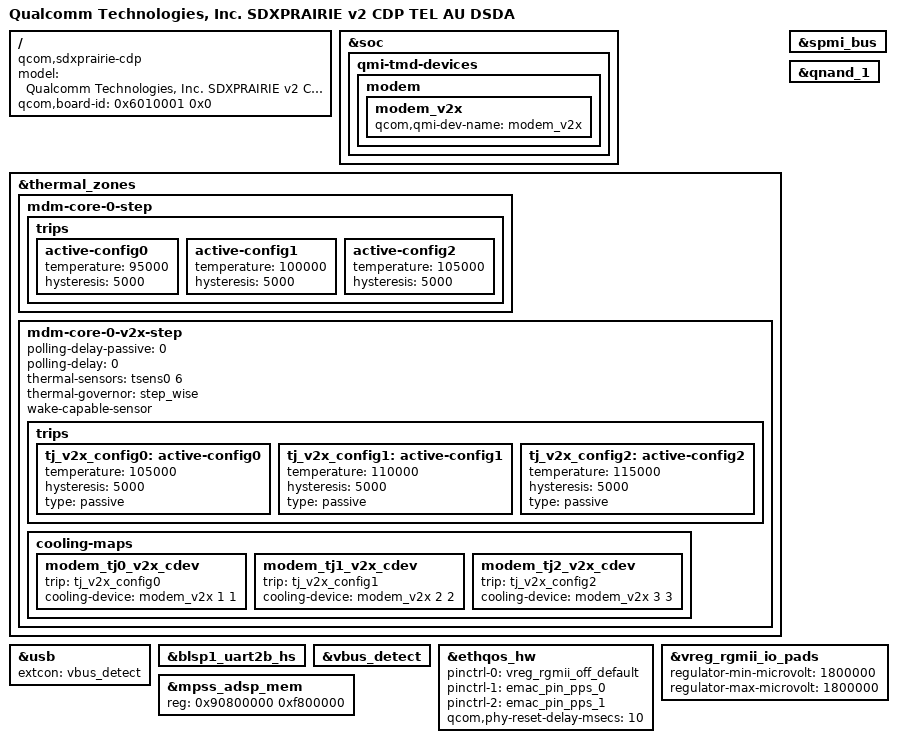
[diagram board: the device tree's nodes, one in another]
/* Copyright (c) 2020, The Linux Foundation. All rights reserved.
 *
 * This program is free software; you can redistribute it and/or modify
 * it under the terms of the GNU General Public License version 2 and
 * only version 2 as published by the Free Software Foundation.
 *
 * This program is distributed in the hope that it will be useful,
 * but WITHOUT ANY WARRANTY; without even the implied warranty of
 * MERCHANTABILITY or FITNESS FOR A PARTICULAR PURPOSE.  See the
 * GNU General Public License for more details.
 */

/dts-v1/;

#include "sdxprairie-v2.dtsi"
#include "sdxprairie-cdp.dtsi"

/ {
	model = "Qualcomm Technologies, Inc. SDXPRAIRIE v2 CDP TEL AU DSDA";
	compatible = "qcom,sdxprairie-cdp",
		"qcom,sdxprairie", "qcom,cdp";
	qcom,board-id = <0x6010001 0x0>;
};

&soc {
	qmi-tmd-devices {
		modem {
			modem_v2x: modem_v2x {
				qcom,qmi-dev-name = "modem_v2x";
				#cooling-cells = <2>;
			};
		};
	};
};

/* delete pm8150b nodes */
&thermal_zones {
	/delete-node/ pm8150b-wp-therm;
	/delete-node/ pm8150b_tz;
	/delete-node/ pm8150b-ibat-lvl0;
	/delete-node/ pm8150b-ibat-lvl1;
	/delete-node/ pm8150b-vbat-lvl0;
	/delete-node/ pm8150b-vbat-lvl1;
	/delete-node/ pm8150b-vbat-lvl2;
	/delete-node/ pm8150b-bcl-lvl0;
	/delete-node/ pm8150b-bcl-lvl1;
	/delete-node/ pm8150b-bcl-lvl2;
	/delete-node/ soc;

	/* update Tj thresholds */
	mdm-core-0-step {
		trips {
			active-config0 {
				temperature = <95000>;
				hysteresis = <5000>;
			};

			active-config1 {
				temperature = <100000>;
				hysteresis = <5000>;
			};

			active-config2 {
				temperature = <105000>;
				hysteresis = <5000>;
			};
		};
	};

	mdm-core-0-v2x-step {
		polling-delay-passive = <0>;
		polling-delay = <0>;
		thermal-sensors = <&tsens0 6>;
		thermal-governor = "step_wise";
		wake-capable-sensor;

		trips {
			tj_v2x_config0: active-config0 {
				temperature = <105000>;
				hysteresis = <5000>;
				type = "passive";
			};

			tj_v2x_config1: active-config1 {
				temperature = <110000>;
				hysteresis = <5000>;
				type = "passive";
			};

			tj_v2x_config2: active-config2 {
				temperature = <115000>;
				hysteresis = <5000>;
				type = "passive";
			};
		};

		cooling-maps {
			modem_tj0_v2x_cdev {
				trip = <&tj_v2x_config0>;
				cooling-device = <&modem_v2x 1 1>;
			};

			modem_tj1_v2x_cdev {
				trip = <&tj_v2x_config1>;
				cooling-device = <&modem_v2x 2 2>;
			};

			modem_tj2_v2x_cdev {
				trip = <&tj_v2x_config2>;
				cooling-device = <&modem_v2x 3 3>;
			};
		};
	};
};

&usb {
	extcon = <&vbus_detect>;
};

&spmi_bus {
	/delete-node/ qpnp,fg;
	/delete-node/ bcl@1d00;
	/delete-node/ qcom,usb-pdphy@1700;
	/delete-node/ qcom,qpnp-smb5;
	/delete-node/ adc_tm@3500;
	/delete-node/ vadc@3100;
	/delete-node/ qcom,pm8150b@2;
	/delete-node/ qcom,pm8150b@3;
};

&qnand_1 {
	status = "ok";
};

&blsp1_uart2b_hs {
	status = "okay";
};

&vbus_detect {
	status = "okay";
};

&ethqos_hw {
	/delete-property/ vreg_rgmii-supply;
	pinctrl-names = "default",
		"dev-emac_pin_pps_0",
		"dev-emac_pin_pps_1";
	pinctrl-0 = <&vreg_rgmii_off_default>;
	pinctrl-1 = <&emac_pin_pps_0>;
	pinctrl-2 = <&emac_pin_pps_1>;
	qcom,phy-reset-delay-msecs = <10>;
};

&vreg_rgmii_io_pads {
	regulator-min-microvolt = <1800000>;
	regulator-max-microvolt = <1800000>;
};

&mpss_adsp_mem {
	reg = <0x90800000 0xf800000>;
};
